AUTOSAR XML (schema 4-0-3)
standard types defined: Boolean, UInt16
package /AUTOSAR_Platform/DataConstrs
  range DC_Boolean: raw 0..1
  range DC_UInt16: raw 0..65535
package /PATAC/MSM/ComponentTypes
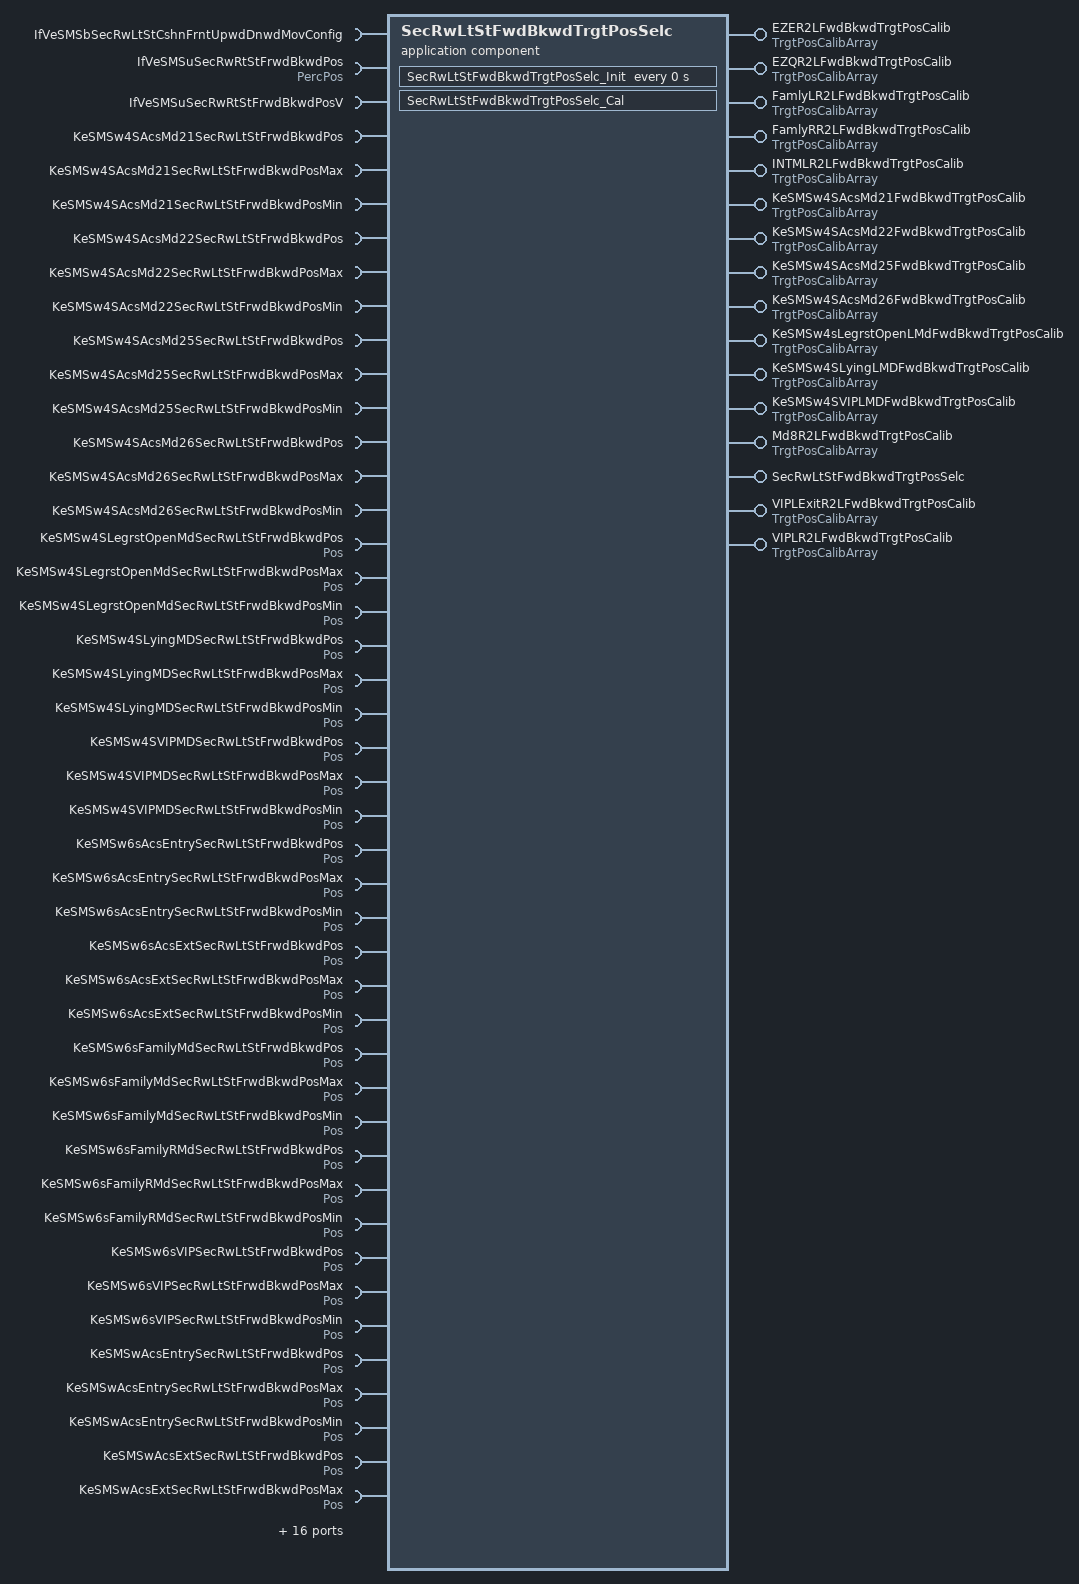
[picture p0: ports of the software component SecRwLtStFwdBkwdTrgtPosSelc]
  application sw component type SecRwLtStFwdBkwdTrgtPosSelc
    16 x provide port:
      EZER2LFwdBkwdTrgtPosCalib: nonqueued-sender-com-spec{data-element=TrgtPosArray, init-value=[4095, 4095, 4095]}, provided-interface=TrgtPosCalibArray
      EZQR2LFwdBkwdTrgtPosCalib: nonqueued-sender-com-spec{data-element=TrgtPosArray, init-value=[4095, 4095, 4095]}, provided-interface=TrgtPosCalibArray
      FamlyLR2LFwdBkwdTrgtPosCalib: nonqueued-sender-com-spec{data-element=TrgtPosArray, init-value=[4095, 4095, 4095]}, provided-interface=TrgtPosCalibArray
      FamlyRR2LFwdBkwdTrgtPosCalib: nonqueued-sender-com-spec{data-element=TrgtPosArray, init-value=[4095, 4095, 4095]}, provided-interface=TrgtPosCalibArray
      INTMLR2LFwdBkwdTrgtPosCalib: nonqueued-sender-com-spec{data-element=TrgtPosArray, init-value=[4095, 4095, 4095]}, provided-interface=TrgtPosCalibArray
      KeSMSw4SAcsMd21FwdBkwdTrgtPosCalib: nonqueued-sender-com-spec{data-element=TrgtPosArray, init-value=[4095, 4095, 4095]}, provided-interface=TrgtPosCalibArray
      KeSMSw4SAcsMd22FwdBkwdTrgtPosCalib: nonqueued-sender-com-spec{data-element=TrgtPosArray, init-value=[4095, 4095, 4095]}, provided-interface=TrgtPosCalibArray
      KeSMSw4SAcsMd25FwdBkwdTrgtPosCalib: nonqueued-sender-com-spec{data-element=TrgtPosArray, init-value=[4095, 4095, 4095]}, provided-interface=TrgtPosCalibArray
      KeSMSw4SAcsMd26FwdBkwdTrgtPosCalib: nonqueued-sender-com-spec{data-element=TrgtPosArray, init-value=[4095, 4095, 4095]}, provided-interface=TrgtPosCalibArray
      KeSMSw4sLegrstOpenLMdFwdBkwdTrgtPosCalib: nonqueued-sender-com-spec{data-element=TrgtPosArray, init-value=[4095, 4095, 4095]}, provided-interface=TrgtPosCalibArray
      KeSMSw4SLyingLMDFwdBkwdTrgtPosCalib: nonqueued-sender-com-spec{data-element=TrgtPosArray, init-value=[4095, 4095, 4095]}, provided-interface=TrgtPosCalibArray
      KeSMSw4SVIPLMDFwdBkwdTrgtPosCalib: nonqueued-sender-com-spec{data-element=TrgtPosArray, init-value=[4095, 4095, 4095]}, provided-interface=TrgtPosCalibArray
      Md8R2LFwdBkwdTrgtPosCalib: nonqueued-sender-com-spec{data-element=TrgtPosArray, init-value=[4095, 4095, 4095]}, provided-interface=TrgtPosCalibArray
      SecRwLtStFwdBkwdTrgtPosSelc: server-com-spec{operation=Cal, queue-length=1}, provided-interface=SecRwLtStFwdBkwdTrgtPosSelc
      VIPLExitR2LFwdBkwdTrgtPosCalib: nonqueued-sender-com-spec{data-element=TrgtPosArray, init-value=[4095, 4095, 4095]}, provided-interface=TrgtPosCalibArray
      VIPLR2LFwdBkwdTrgtPosCalib: nonqueued-sender-com-spec{data-element=TrgtPosArray, init-value=[4095, 4095, 4095]}, provided-interface=TrgtPosCalibArray
    60 x require port:
      IfVeSMSbSecRwLtStCshnFrntUpwdDnwdMovConfig: nonqueued-receiver-com-spec{data-element=IfVeSMSbSecRwLtStCshnFrntUpwdDnwdMovConfig/Val, filter=data-filter-type=ALWAYS, init-value=0}, required-interface=IfVeSMSbSecRwLtStCshnFrntUpwdDnwdMovConfig
      IfVeSMSuSecRwRtStFrwdBkwdPos: nonqueued-receiver-com-spec{data-element=PercPos/Val, filter=data-filter-type=ALWAYS, init-value=0}, required-interface=PercPos
      IfVeSMSuSecRwRtStFrwdBkwdPosV: nonqueued-receiver-com-spec{data-element=IfVeSMSuSecRwRtStFrwdBkwdPosV/Val, filter=data-filter-type=ALWAYS, init-value=0}, required-interface=IfVeSMSuSecRwRtStFrwdBkwdPosV
      KeSMSw4SAcsMd21SecRwLtStFrwdBkwdPos: parameter-require-com-spec{init-value=0, parameter=KeSMSw4SAcsMd21SecRwLtStFrwdBkwdPos/Val}, required-interface=KeSMSw4SAcsMd21SecRwLtStFrwdBkwdPos
      KeSMSw4SAcsMd21SecRwLtStFrwdBkwdPosMax: parameter-require-com-spec{init-value=0, parameter=KeSMSw4SAcsMd21SecRwLtStFrwdBkwdPosMax/Val}, required-interface=KeSMSw4SAcsMd21SecRwLtStFrwdBkwdPosMax
      KeSMSw4SAcsMd21SecRwLtStFrwdBkwdPosMin: parameter-require-com-spec{init-value=0, parameter=KeSMSw4SAcsMd21SecRwLtStFrwdBkwdPosMin/Val}, required-interface=KeSMSw4SAcsMd21SecRwLtStFrwdBkwdPosMin
      KeSMSw4SAcsMd22SecRwLtStFrwdBkwdPos: parameter-require-com-spec{init-value=0, parameter=KeSMSw4SAcsMd22SecRwLtStFrwdBkwdPos/Val}, required-interface=KeSMSw4SAcsMd22SecRwLtStFrwdBkwdPos
      KeSMSw4SAcsMd22SecRwLtStFrwdBkwdPosMax: parameter-require-com-spec{init-value=0, parameter=KeSMSw4SAcsMd22SecRwLtStFrwdBkwdPosMax/Val}, required-interface=KeSMSw4SAcsMd22SecRwLtStFrwdBkwdPosMax
      KeSMSw4SAcsMd22SecRwLtStFrwdBkwdPosMin: parameter-require-com-spec{init-value=0, parameter=KeSMSw4SAcsMd22SecRwLtStFrwdBkwdPosMin/Val}, required-interface=KeSMSw4SAcsMd22SecRwLtStFrwdBkwdPosMin
      KeSMSw4SAcsMd25SecRwLtStFrwdBkwdPos: parameter-require-com-spec{init-value=0, parameter=KeSMSw4SAcsMd25SecRwLtStFrwdBkwdPos/Val}, required-interface=KeSMSw4SAcsMd25SecRwLtStFrwdBkwdPos
      KeSMSw4SAcsMd25SecRwLtStFrwdBkwdPosMax: parameter-require-com-spec{init-value=0, parameter=KeSMSw4SAcsMd25SecRwLtStFrwdBkwdPosMax/Val}, required-interface=KeSMSw4SAcsMd25SecRwLtStFrwdBkwdPosMax
      KeSMSw4SAcsMd25SecRwLtStFrwdBkwdPosMin: parameter-require-com-spec{init-value=0, parameter=KeSMSw4SAcsMd25SecRwLtStFrwdBkwdPosMin/Val}, required-interface=KeSMSw4SAcsMd25SecRwLtStFrwdBkwdPosMin
      KeSMSw4SAcsMd26SecRwLtStFrwdBkwdPos: parameter-require-com-spec{init-value=0, parameter=KeSMSw4SAcsMd26SecRwLtStFrwdBkwdPos/Val}, required-interface=KeSMSw4SAcsMd26SecRwLtStFrwdBkwdPos
      KeSMSw4SAcsMd26SecRwLtStFrwdBkwdPosMax: parameter-require-com-spec{init-value=0, parameter=KeSMSw4SAcsMd26SecRwLtStFrwdBkwdPosMax/Val}, required-interface=KeSMSw4SAcsMd26SecRwLtStFrwdBkwdPosMax
      KeSMSw4SAcsMd26SecRwLtStFrwdBkwdPosMin: parameter-require-com-spec{init-value=0, parameter=KeSMSw4SAcsMd26SecRwLtStFrwdBkwdPosMin/Val}, required-interface=KeSMSw4SAcsMd26SecRwLtStFrwdBkwdPosMin
      KeSMSw4SLegrstOpenMdSecRwLtStFrwdBkwdPos: parameter-require-com-spec{init-value=2920, parameter=Pos/Val}, required-interface=Pos
      KeSMSw4SLegrstOpenMdSecRwLtStFrwdBkwdPosMax: parameter-require-com-spec{init-value=2920, parameter=Pos/Val}, required-interface=Pos
      KeSMSw4SLegrstOpenMdSecRwLtStFrwdBkwdPosMin: parameter-require-com-spec{init-value=2920, parameter=Pos/Val}, required-interface=Pos
      KeSMSw4SLyingMDSecRwLtStFrwdBkwdPos: parameter-require-com-spec{init-value=2920, parameter=Pos/Val}, required-interface=Pos
      KeSMSw4SLyingMDSecRwLtStFrwdBkwdPosMax: parameter-require-com-spec{init-value=2920, parameter=Pos/Val}, required-interface=Pos
      KeSMSw4SLyingMDSecRwLtStFrwdBkwdPosMin: parameter-require-com-spec{init-value=2920, parameter=Pos/Val}, required-interface=Pos
      KeSMSw4SVIPMDSecRwLtStFrwdBkwdPos: parameter-require-com-spec{init-value=2920, parameter=Pos/Val}, required-interface=Pos
      KeSMSw4SVIPMDSecRwLtStFrwdBkwdPosMax: parameter-require-com-spec{init-value=2920, parameter=Pos/Val}, required-interface=Pos
      KeSMSw4SVIPMDSecRwLtStFrwdBkwdPosMin: parameter-require-com-spec{init-value=2920, parameter=Pos/Val}, required-interface=Pos
      KeSMSw6sAcsEntrySecRwLtStFrwdBkwdPos: parameter-require-com-spec{init-value=727, parameter=Pos/Val}, required-interface=Pos
      KeSMSw6sAcsEntrySecRwLtStFrwdBkwdPosMax: parameter-require-com-spec{init-value=727, parameter=Pos/Val}, required-interface=Pos
      KeSMSw6sAcsEntrySecRwLtStFrwdBkwdPosMin: parameter-require-com-spec{init-value=727, parameter=Pos/Val}, required-interface=Pos
      KeSMSw6sAcsExtSecRwLtStFrwdBkwdPos: parameter-require-com-spec{init-value=727, parameter=Pos/Val}, required-interface=Pos
      KeSMSw6sAcsExtSecRwLtStFrwdBkwdPosMax: parameter-require-com-spec{init-value=727, parameter=Pos/Val}, required-interface=Pos
      KeSMSw6sAcsExtSecRwLtStFrwdBkwdPosMin: parameter-require-com-spec{init-value=727, parameter=Pos/Val}, required-interface=Pos
      KeSMSw6sFamilyMdSecRwLtStFrwdBkwdPos: parameter-require-com-spec{init-value=0, parameter=Pos/Val}, required-interface=Pos
      KeSMSw6sFamilyMdSecRwLtStFrwdBkwdPosMax: parameter-require-com-spec{init-value=0, parameter=Pos/Val}, required-interface=Pos
      KeSMSw6sFamilyMdSecRwLtStFrwdBkwdPosMin: parameter-require-com-spec{init-value=0, parameter=Pos/Val}, required-interface=Pos
      KeSMSw6sFamilyRMdSecRwLtStFrwdBkwdPos: parameter-require-com-spec{init-value=0, parameter=Pos/Val}, required-interface=Pos
      KeSMSw6sFamilyRMdSecRwLtStFrwdBkwdPosMax: parameter-require-com-spec{init-value=0, parameter=Pos/Val}, required-interface=Pos
      KeSMSw6sFamilyRMdSecRwLtStFrwdBkwdPosMin: parameter-require-com-spec{init-value=0, parameter=Pos/Val}, required-interface=Pos
      KeSMSw6sVIPSecRwLtStFrwdBkwdPos: parameter-require-com-spec{init-value=2920, parameter=Pos/Val}, required-interface=Pos
      KeSMSw6sVIPSecRwLtStFrwdBkwdPosMax: parameter-require-com-spec{init-value=2920, parameter=Pos/Val}, required-interface=Pos
      KeSMSw6sVIPSecRwLtStFrwdBkwdPosMin: parameter-require-com-spec{init-value=2920, parameter=Pos/Val}, required-interface=Pos
      KeSMSwAcsEntrySecRwLtStFrwdBkwdPos: parameter-require-com-spec{init-value=727, parameter=Pos/Val}, required-interface=Pos
      KeSMSwAcsEntrySecRwLtStFrwdBkwdPosMax: parameter-require-com-spec{init-value=727, parameter=Pos/Val}, required-interface=Pos
      KeSMSwAcsEntrySecRwLtStFrwdBkwdPosMin: parameter-require-com-spec{init-value=727, parameter=Pos/Val}, required-interface=Pos
      KeSMSwAcsExtSecRwLtStFrwdBkwdPos: parameter-require-com-spec{init-value=727, parameter=Pos/Val}, required-interface=Pos
      KeSMSwAcsExtSecRwLtStFrwdBkwdPosMax: parameter-require-com-spec{init-value=727, parameter=Pos/Val}, required-interface=Pos
      KeSMSwAcsExtSecRwLtStFrwdBkwdPosMin: parameter-require-com-spec{init-value=727, parameter=Pos/Val}, required-interface=Pos
      KeSMSwAcsMd8SecRwLtStFrwdBkwdPos: parameter-require-com-spec{init-value=0, parameter=Pos/Val}, required-interface=Pos
      KeSMSwAcsMd8SecRwLtStFrwdBkwdPosMax: parameter-require-com-spec{init-value=0, parameter=Pos/Val}, required-interface=Pos
      KeSMSwAcsMd8SecRwLtStFrwdBkwdPosMin: parameter-require-com-spec{init-value=0, parameter=Pos/Val}, required-interface=Pos
      KeSMSwFamilyMdSecRwLtStFrwdBkwdPos: parameter-require-com-spec{init-value=0, parameter=Pos/Val}, required-interface=Pos
      KeSMSwFamilyMdSecRwLtStFrwdBkwdPosMax: parameter-require-com-spec{init-value=0, parameter=Pos/Val}, required-interface=Pos
      KeSMSwFamilyMdSecRwLtStFrwdBkwdPosMin: parameter-require-com-spec{init-value=0, parameter=Pos/Val}, required-interface=Pos
      KeSMSwFamilyRMdSecRwLtStFrwdBkwdPos: parameter-require-com-spec{init-value=0, parameter=Pos/Val}, required-interface=Pos
      KeSMSwFamilyRMdSecRwLtStFrwdBkwdPosMax: parameter-require-com-spec{init-value=0, parameter=Pos/Val}, required-interface=Pos
      KeSMSwFamilyRMdSecRwLtStFrwdBkwdPosMin: parameter-require-com-spec{init-value=0, parameter=Pos/Val}, required-interface=Pos
      KeSMSwVIPSecRwLtStFrwdBkwdPos: parameter-require-com-spec{init-value=2920, parameter=Pos/Val}, required-interface=Pos
      KeSMSwVIPSecRwLtStFrwdBkwdPosMax: parameter-require-com-spec{init-value=2920, parameter=Pos/Val}, required-interface=Pos
      KeSMSwVIPSecRwLtStFrwdBkwdPosMin: parameter-require-com-spec{init-value=2920, parameter=Pos/Val}, required-interface=Pos
      StNumFlg: required-interface=StNumFlg
        required-com-specs:
          data-element=Is4s, filter=data-filter-type=ALWAYS, init-value=0
          data-element=Is6s, filter=data-filter-type=ALWAYS, init-value=0
          data-element=Is6s7s, filter=data-filter-type=ALWAYS, init-value=0
          data-element=Is7s, filter=data-filter-type=ALWAYS, init-value=0
      VIPL557TrgtPos: required-com-specs=[VIPL557TrgtPos/Get, VIPL557TrgtPos/Set], required-interface=VIPL557TrgtPos
      VIPLExit557TrgtPos: required-com-specs=[VIPLExit557TrgtPos/Get, VIPLExit557TrgtPos/Set], required-interface=VIPLExit557TrgtPos
    behavior SecRwLtStFwdBkwdTrgtPosSelc_InternalBehavior
      operation invoked event OIT_SecRwLtStFwdBkwdTrgtPosSelc_Cal_SecRwLtStFwdBkwdTrgtPosSelc_Cal: start-on-event=SecRwLtStFwdBkwdTrgtPosSelc_Cal, operation=SecRwLtStFwdBkwdTrgtPosSelc.Cal
      timing event SecRwLtStFwdBkwdTrgtPosSelc_InitEvent: start-on-event=SecRwLtStFwdBkwdTrgtPosSelc_Init, period=0
      runnable SecRwLtStFwdBkwdTrgtPosSelc_Cal
        data-receive-point-by-arguments:
          7 x access:
            REC_IfVeSMSbSecRwLtStCshnFrntUpwdDnwdMovConfig_Val: accessed-variable=IfVeSMSbSecRwLtStCshnFrntUpwdDnwdMovConfig.Val
            REC_IfVeSMSuSecRwRtStFrwdBkwdPos_Val: accessed-variable=IfVeSMSuSecRwRtStFrwdBkwdPos.Val
            REC_IfVeSMSuSecRwRtStFrwdBkwdPosV_Val: accessed-variable=IfVeSMSuSecRwRtStFrwdBkwdPosV.Val
            REC_StNumFlg_Is4s: accessed-variable=StNumFlg.Is4s
            REC_StNumFlg_Is6s: accessed-variable=StNumFlg.Is6s
            REC_StNumFlg_Is6s7s: accessed-variable=StNumFlg.Is6s7s
            REC_StNumFlg_Is7s: accessed-variable=StNumFlg.Is7s
        data-send-points:
          15 x access:
            SEND_EZER2LFwdBkwdTrgtPosCalib_TrgtPosArray: accessed-variable=EZER2LFwdBkwdTrgtPosCalib.TrgtPosArray
            SEND_EZQR2LFwdBkwdTrgtPosCalib_TrgtPosArray: accessed-variable=EZQR2LFwdBkwdTrgtPosCalib.TrgtPosArray
            SEND_FamlyLR2LFwdBkwdTrgtPosCalib_TrgtPosArray: accessed-variable=FamlyLR2LFwdBkwdTrgtPosCalib.TrgtPosArray
            SEND_FamlyRR2LFwdBkwdTrgtPosCalib_TrgtPosArray: accessed-variable=FamlyRR2LFwdBkwdTrgtPosCalib.TrgtPosArray
            SEND_INTMLR2LFwdBkwdTrgtPosCalib_TrgtPosArray: accessed-variable=INTMLR2LFwdBkwdTrgtPosCalib.TrgtPosArray
            SEND_KeSMSw4SAcsMd21FwdBkwdTrgtPosCalib_TrgtPosArray: accessed-variable=KeSMSw4SAcsMd21FwdBkwdTrgtPosCalib.TrgtPosArray
            SEND_KeSMSw4SAcsMd22FwdBkwdTrgtPosCalib_TrgtPosArray: accessed-variable=KeSMSw4SAcsMd22FwdBkwdTrgtPosCalib.TrgtPosArray
            SEND_KeSMSw4SAcsMd25FwdBkwdTrgtPosCalib_TrgtPosArray: accessed-variable=KeSMSw4SAcsMd25FwdBkwdTrgtPosCalib.TrgtPosArray
            SEND_KeSMSw4SAcsMd26FwdBkwdTrgtPosCalib_TrgtPosArray: accessed-variable=KeSMSw4SAcsMd26FwdBkwdTrgtPosCalib.TrgtPosArray
            SEND_KeSMSw4sLgrstOpenLFwdBkwdTrgtPosCalib_TrgtPosArray: accessed-variable=KeSMSw4sLegrstOpenLMdFwdBkwdTrgtPosCalib.TrgtPosArray
            SEND_KeSMSw4SLyingLFwdBkwdTrgtPosCalib_TrgtPosArray: accessed-variable=KeSMSw4SLyingLMDFwdBkwdTrgtPosCalib.TrgtPosArray
            SEND_KeSMSw4SVIPLFwdBkwdTrgtPosCalib_TrgtPosArray: accessed-variable=KeSMSw4SVIPLMDFwdBkwdTrgtPosCalib.TrgtPosArray
            SEND_Md8R2LFwdBkwdTrgtPosCalib_TrgtPosArray: accessed-variable=Md8R2LFwdBkwdTrgtPosCalib.TrgtPosArray
            SEND_VIPLExitR2LFwdBkwdTrgtPosCalib_TrgtPosArray: accessed-variable=VIPLExitR2LFwdBkwdTrgtPosCalib.TrgtPosArray
            SEND_VIPLR2LFwdBkwdTrgtPosCalib_TrgtPosArray: accessed-variable=VIPLR2LFwdBkwdTrgtPosCalib.TrgtPosArray
        54 x parameter access:
          PA_KeSMSw4SAcsMd21SecRwLtStFrwdBkwdPos_Val: accessed-parameter=KeSMSw4SAcsMd21SecRwLtStFrwdBkwdPos.Val
          PA_KeSMSw4SAcsMd21SecRwLtStFrwdBkwdPosMax_Val: accessed-parameter=KeSMSw4SAcsMd21SecRwLtStFrwdBkwdPosMax.Val
          PA_KeSMSw4SAcsMd21SecRwLtStFrwdBkwdPosMin_Val: accessed-parameter=KeSMSw4SAcsMd21SecRwLtStFrwdBkwdPosMin.Val
          PA_KeSMSw4SAcsMd22SecRwLtStFrwdBkwdPos_Val: accessed-parameter=KeSMSw4SAcsMd22SecRwLtStFrwdBkwdPos.Val
          PA_KeSMSw4SAcsMd22SecRwLtStFrwdBkwdPosMax_Val: accessed-parameter=KeSMSw4SAcsMd22SecRwLtStFrwdBkwdPosMax.Val
          PA_KeSMSw4SAcsMd22SecRwLtStFrwdBkwdPosMin_Val: accessed-parameter=KeSMSw4SAcsMd22SecRwLtStFrwdBkwdPosMin.Val
          PA_KeSMSw4SAcsMd25SecRwLtStFrwdBkwdPos_Val: accessed-parameter=KeSMSw4SAcsMd25SecRwLtStFrwdBkwdPos.Val
          PA_KeSMSw4SAcsMd25SecRwLtStFrwdBkwdPosMax_Val: accessed-parameter=KeSMSw4SAcsMd25SecRwLtStFrwdBkwdPosMax.Val
          PA_KeSMSw4SAcsMd25SecRwLtStFrwdBkwdPosMin_Val: accessed-parameter=KeSMSw4SAcsMd25SecRwLtStFrwdBkwdPosMin.Val
          PA_KeSMSw4SAcsMd26SecRwLtStFrwdBkwdPos_Val: accessed-parameter=KeSMSw4SAcsMd26SecRwLtStFrwdBkwdPos.Val
          PA_KeSMSw4SAcsMd26SecRwLtStFrwdBkwdPosMax_Val: accessed-parameter=KeSMSw4SAcsMd26SecRwLtStFrwdBkwdPosMax.Val
          PA_KeSMSw4SAcsMd26SecRwLtStFrwdBkwdPosMin_Val: accessed-parameter=KeSMSw4SAcsMd26SecRwLtStFrwdBkwdPosMin.Val
          PA_KeSMSw4SLegrstOpenMdSecRwLtStFrwdBkwdPos_Val: accessed-parameter=KeSMSw4SLegrstOpenMdSecRwLtStFrwdBkwdPos.Val
          PA_KeSMSw4SLegrstOpenMdSecRwLtStFrwdBkwdPosMax_Val: accessed-parameter=KeSMSw4SLegrstOpenMdSecRwLtStFrwdBkwdPosMax.Val
          PA_KeSMSw4SLegrstOpenMdSecRwLtStFrwdBkwdPosMin_Val: accessed-parameter=KeSMSw4SLegrstOpenMdSecRwLtStFrwdBkwdPosMin.Val
          PA_KeSMSw4SLyingMDSecRwLtStFrwdBkwdPos_Val: accessed-parameter=KeSMSw4SLyingMDSecRwLtStFrwdBkwdPos.Val
          PA_KeSMSw4SLyingMDSecRwLtStFrwdBkwdPosMax_Val: accessed-parameter=KeSMSw4SLyingMDSecRwLtStFrwdBkwdPosMax.Val
          PA_KeSMSw4SLyingMDSecRwLtStFrwdBkwdPosMin_Val: accessed-parameter=KeSMSw4SLyingMDSecRwLtStFrwdBkwdPosMin.Val
          PA_KeSMSw4SVIPMDSecRwLtStFrwdBkwdPos_Val: accessed-parameter=KeSMSw4SVIPMDSecRwLtStFrwdBkwdPos.Val
          PA_KeSMSw4SVIPMDSecRwLtStFrwdBkwdPosMax_Val: accessed-parameter=KeSMSw4SVIPMDSecRwLtStFrwdBkwdPosMax.Val
          PA_KeSMSw4SVIPMDSecRwLtStFrwdBkwdPosMin_Val: accessed-parameter=KeSMSw4SVIPMDSecRwLtStFrwdBkwdPosMin.Val
          PA_KeSMSw6sAcsEntrySecRwLtStFrwdBkwdPos_Val: accessed-parameter=KeSMSw6sAcsEntrySecRwLtStFrwdBkwdPos.Val
          PA_KeSMSw6sAcsEntrySecRwLtStFrwdBkwdPosMax_Val: accessed-parameter=KeSMSw6sAcsEntrySecRwLtStFrwdBkwdPosMax.Val
          PA_KeSMSw6sAcsEntrySecRwLtStFrwdBkwdPosMin_Val: accessed-parameter=KeSMSw6sAcsEntrySecRwLtStFrwdBkwdPosMin.Val
          PA_KeSMSw6sAcsExtSecRwLtStFrwdBkwdPos_Val: accessed-parameter=KeSMSw6sAcsExtSecRwLtStFrwdBkwdPos.Val
          PA_KeSMSw6sAcsExtSecRwLtStFrwdBkwdPosMax_Val: accessed-parameter=KeSMSw6sAcsExtSecRwLtStFrwdBkwdPosMax.Val
          PA_KeSMSw6sAcsExtSecRwLtStFrwdBkwdPosMin_Val: accessed-parameter=KeSMSw6sAcsExtSecRwLtStFrwdBkwdPosMin.Val
          PA_KeSMSw6sFamilyMdSecRwLtStFrwdBkwdPos_Val: accessed-parameter=KeSMSw6sFamilyMdSecRwLtStFrwdBkwdPos.Val
          PA_KeSMSw6sFamilyMdSecRwLtStFrwdBkwdPosMax_Val: accessed-parameter=KeSMSw6sFamilyMdSecRwLtStFrwdBkwdPosMax.Val
          PA_KeSMSw6sFamilyMdSecRwLtStFrwdBkwdPosMin_Val: accessed-parameter=KeSMSw6sFamilyMdSecRwLtStFrwdBkwdPosMin.Val
          PA_KeSMSw6sFamilyRMdSecRwLtStFrwdBkwdPos_Val: accessed-parameter=KeSMSw6sFamilyRMdSecRwLtStFrwdBkwdPos.Val
          PA_KeSMSw6sFamilyRMdSecRwLtStFrwdBkwdPosMax_Val: accessed-parameter=KeSMSw6sFamilyRMdSecRwLtStFrwdBkwdPosMax.Val
          PA_KeSMSw6sFamilyRMdSecRwLtStFrwdBkwdPosMin_Val: accessed-parameter=KeSMSw6sFamilyRMdSecRwLtStFrwdBkwdPosMin.Val
          PA_KeSMSw6sVIPSecRwLtStFrwdBkwdPos_Val: accessed-parameter=KeSMSw6sVIPSecRwLtStFrwdBkwdPos.Val
          PA_KeSMSw6sVIPSecRwLtStFrwdBkwdPosMax_Val: accessed-parameter=KeSMSw6sVIPSecRwLtStFrwdBkwdPosMax.Val
          PA_KeSMSw6sVIPSecRwLtStFrwdBkwdPosMin_Val: accessed-parameter=KeSMSw6sVIPSecRwLtStFrwdBkwdPosMin.Val
          PA_KeSMSwAcsEntrySecRwLtStFrwdBkwdPos_Val: accessed-parameter=KeSMSwAcsEntrySecRwLtStFrwdBkwdPos.Val
          PA_KeSMSwAcsEntrySecRwLtStFrwdBkwdPosMax_Val: accessed-parameter=KeSMSwAcsEntrySecRwLtStFrwdBkwdPosMax.Val
          PA_KeSMSwAcsEntrySecRwLtStFrwdBkwdPosMin_Val: accessed-parameter=KeSMSwAcsEntrySecRwLtStFrwdBkwdPosMin.Val
          PA_KeSMSwAcsExtSecRwLtStFrwdBkwdPos_Val: accessed-parameter=KeSMSwAcsExtSecRwLtStFrwdBkwdPos.Val
          PA_KeSMSwAcsExtSecRwLtStFrwdBkwdPosMax_Val: accessed-parameter=KeSMSwAcsExtSecRwLtStFrwdBkwdPosMax.Val
          PA_KeSMSwAcsExtSecRwLtStFrwdBkwdPosMin_Val: accessed-parameter=KeSMSwAcsExtSecRwLtStFrwdBkwdPosMin.Val
          PA_KeSMSwAcsMd8SecRwLtStFrwdBkwdPos_Val: accessed-parameter=KeSMSwAcsMd8SecRwLtStFrwdBkwdPos.Val
          PA_KeSMSwAcsMd8SecRwLtStFrwdBkwdPosMax_Val: accessed-parameter=KeSMSwAcsMd8SecRwLtStFrwdBkwdPosMax.Val
          PA_KeSMSwAcsMd8SecRwLtStFrwdBkwdPosMin_Val: accessed-parameter=KeSMSwAcsMd8SecRwLtStFrwdBkwdPosMin.Val
          PA_KeSMSwFamilyMdSecRwLtStFrwdBkwdPos_Val: accessed-parameter=KeSMSwFamilyMdSecRwLtStFrwdBkwdPos.Val
          PA_KeSMSwFamilyMdSecRwLtStFrwdBkwdPosMax_Val: accessed-parameter=KeSMSwFamilyMdSecRwLtStFrwdBkwdPosMax.Val
          PA_KeSMSwFamilyMdSecRwLtStFrwdBkwdPosMin_Val: accessed-parameter=KeSMSwFamilyMdSecRwLtStFrwdBkwdPosMin.Val
          PA_KeSMSwFamilyRMdSecRwLtStFrwdBkwdPos_Val: accessed-parameter=KeSMSwFamilyRMdSecRwLtStFrwdBkwdPos.Val
          PA_KeSMSwFamilyRMdSecRwLtStFrwdBkwdPosMax_Val: accessed-parameter=KeSMSwFamilyRMdSecRwLtStFrwdBkwdPosMax.Val
          PA_KeSMSwFamilyRMdSecRwLtStFrwdBkwdPosMin_Val: accessed-parameter=KeSMSwFamilyRMdSecRwLtStFrwdBkwdPosMin.Val
          PA_KeSMSwVIPSecRwLtStFrwdBkwdPos_Val: accessed-parameter=KeSMSwVIPSecRwLtStFrwdBkwdPos.Val
          PA_KeSMSwVIPSecRwLtStFrwdBkwdPosMax_Val: accessed-parameter=KeSMSwVIPSecRwLtStFrwdBkwdPosMax.Val
          PA_KeSMSwVIPSecRwLtStFrwdBkwdPosMin_Val: accessed-parameter=KeSMSwVIPSecRwLtStFrwdBkwdPosMin.Val
        sync call SC_VIPL557TrgtPos_Get: operation=VIPL557TrgtPos.Get, timeout=0
        sync call SC_VIPLExit557TrgtPos_Get: operation=VIPLExit557TrgtPos.Get, timeout=0
      runnable SecRwLtStFwdBkwdTrgtPosSelc_Init
        54 x parameter access:
          PA_KeSMSw4SAcsMd21SecRwLtStFrwdBkwdPos_Val: accessed-parameter=KeSMSw4SAcsMd21SecRwLtStFrwdBkwdPos.Val
          PA_KeSMSw4SAcsMd21SecRwLtStFrwdBkwdPosMax_Val: accessed-parameter=KeSMSw4SAcsMd21SecRwLtStFrwdBkwdPosMax.Val
          PA_KeSMSw4SAcsMd21SecRwLtStFrwdBkwdPosMin_Val: accessed-parameter=KeSMSw4SAcsMd21SecRwLtStFrwdBkwdPosMin.Val
          PA_KeSMSw4SAcsMd22SecRwLtStFrwdBkwdPos_Val: accessed-parameter=KeSMSw4SAcsMd22SecRwLtStFrwdBkwdPos.Val
          PA_KeSMSw4SAcsMd22SecRwLtStFrwdBkwdPosMax_Val: accessed-parameter=KeSMSw4SAcsMd22SecRwLtStFrwdBkwdPosMax.Val
          PA_KeSMSw4SAcsMd22SecRwLtStFrwdBkwdPosMin_Val: accessed-parameter=KeSMSw4SAcsMd22SecRwLtStFrwdBkwdPosMin.Val
          PA_KeSMSw4SAcsMd25SecRwLtStFrwdBkwdPos_Val: accessed-parameter=KeSMSw4SAcsMd25SecRwLtStFrwdBkwdPos.Val
          PA_KeSMSw4SAcsMd25SecRwLtStFrwdBkwdPosMax_Val: accessed-parameter=KeSMSw4SAcsMd25SecRwLtStFrwdBkwdPosMax.Val
          PA_KeSMSw4SAcsMd25SecRwLtStFrwdBkwdPosMin_Val: accessed-parameter=KeSMSw4SAcsMd25SecRwLtStFrwdBkwdPosMin.Val
          PA_KeSMSw4SAcsMd26SecRwLtStFrwdBkwdPos_Val: accessed-parameter=KeSMSw4SAcsMd26SecRwLtStFrwdBkwdPos.Val
          PA_KeSMSw4SAcsMd26SecRwLtStFrwdBkwdPosMax_Val: accessed-parameter=KeSMSw4SAcsMd26SecRwLtStFrwdBkwdPosMax.Val
          PA_KeSMSw4SAcsMd26SecRwLtStFrwdBkwdPosMin_Val: accessed-parameter=KeSMSw4SAcsMd26SecRwLtStFrwdBkwdPosMin.Val
          PA_KeSMSw4SLegrstOpenMdSecRwLtStFrwdBkwdPos_Val: accessed-parameter=KeSMSw4SLegrstOpenMdSecRwLtStFrwdBkwdPos.Val
          PA_KeSMSw4SLegrstOpenMdSecRwLtStFrwdBkwdPosMax_Val: accessed-parameter=KeSMSw4SLegrstOpenMdSecRwLtStFrwdBkwdPosMax.Val
          PA_KeSMSw4SLegrstOpenMdSecRwLtStFrwdBkwdPosMin_Val: accessed-parameter=KeSMSw4SLegrstOpenMdSecRwLtStFrwdBkwdPosMin.Val
          PA_KeSMSw4SLyingMDSecRwLtStFrwdBkwdPos_Val: accessed-parameter=KeSMSw4SLyingMDSecRwLtStFrwdBkwdPos.Val
          PA_KeSMSw4SLyingMDSecRwLtStFrwdBkwdPosMax_Val: accessed-parameter=KeSMSw4SLyingMDSecRwLtStFrwdBkwdPosMax.Val
          PA_KeSMSw4SLyingMDSecRwLtStFrwdBkwdPosMin_Val: accessed-parameter=KeSMSw4SLyingMDSecRwLtStFrwdBkwdPosMin.Val
          PA_KeSMSw4SVIPMDSecRwLtStFrwdBkwdPos_Val: accessed-parameter=KeSMSw4SVIPMDSecRwLtStFrwdBkwdPos.Val
          PA_KeSMSw4SVIPMDSecRwLtStFrwdBkwdPosMax_Val: accessed-parameter=KeSMSw4SVIPMDSecRwLtStFrwdBkwdPosMax.Val
          PA_KeSMSw4SVIPMDSecRwLtStFrwdBkwdPosMin_Val: accessed-parameter=KeSMSw4SVIPMDSecRwLtStFrwdBkwdPosMin.Val
          PA_KeSMSw6sAcsEntrySecRwLtStFrwdBkwdPos_Val: accessed-parameter=KeSMSw6sAcsEntrySecRwLtStFrwdBkwdPos.Val
          PA_KeSMSw6sAcsEntrySecRwLtStFrwdBkwdPosMax_Val: accessed-parameter=KeSMSw6sAcsEntrySecRwLtStFrwdBkwdPosMax.Val
          PA_KeSMSw6sAcsEntrySecRwLtStFrwdBkwdPosMin_Val: accessed-parameter=KeSMSw6sAcsEntrySecRwLtStFrwdBkwdPosMin.Val
          PA_KeSMSw6sAcsExtSecRwLtStFrwdBkwdPos_Val: accessed-parameter=KeSMSw6sAcsExtSecRwLtStFrwdBkwdPos.Val
          PA_KeSMSw6sAcsExtSecRwLtStFrwdBkwdPosMax_Val: accessed-parameter=KeSMSw6sAcsExtSecRwLtStFrwdBkwdPosMax.Val
          PA_KeSMSw6sAcsExtSecRwLtStFrwdBkwdPosMin_Val: accessed-parameter=KeSMSw6sAcsExtSecRwLtStFrwdBkwdPosMin.Val
          PA_KeSMSw6sFamilyMdSecRwLtStFrwdBkwdPos_Val: accessed-parameter=KeSMSw6sFamilyMdSecRwLtStFrwdBkwdPos.Val
          PA_KeSMSw6sFamilyMdSecRwLtStFrwdBkwdPosMax_Val: accessed-parameter=KeSMSw6sFamilyMdSecRwLtStFrwdBkwdPosMax.Val
          PA_KeSMSw6sFamilyMdSecRwLtStFrwdBkwdPosMin_Val: accessed-parameter=KeSMSw6sFamilyMdSecRwLtStFrwdBkwdPosMin.Val
          PA_KeSMSw6sFamilyRMdSecRwLtStFrwdBkwdPos_Val: accessed-parameter=KeSMSw6sFamilyRMdSecRwLtStFrwdBkwdPos.Val
          PA_KeSMSw6sFamilyRMdSecRwLtStFrwdBkwdPosMax_Val: accessed-parameter=KeSMSw6sFamilyRMdSecRwLtStFrwdBkwdPosMax.Val
          PA_KeSMSw6sFamilyRMdSecRwLtStFrwdBkwdPosMin_Val: accessed-parameter=KeSMSw6sFamilyRMdSecRwLtStFrwdBkwdPosMin.Val
          PA_KeSMSw6sVIPSecRwLtStFrwdBkwdPos_Val: accessed-parameter=KeSMSw6sVIPSecRwLtStFrwdBkwdPos.Val
          PA_KeSMSw6sVIPSecRwLtStFrwdBkwdPosMax_Val: accessed-parameter=KeSMSw6sVIPSecRwLtStFrwdBkwdPosMax.Val
          PA_KeSMSw6sVIPSecRwLtStFrwdBkwdPosMin_Val: accessed-parameter=KeSMSw6sVIPSecRwLtStFrwdBkwdPosMin.Val
          PA_KeSMSwAcsEntrySecRwLtStFrwdBkwdPos_Val: accessed-parameter=KeSMSwAcsEntrySecRwLtStFrwdBkwdPos.Val
          PA_KeSMSwAcsEntrySecRwLtStFrwdBkwdPosMax_Val: accessed-parameter=KeSMSwAcsEntrySecRwLtStFrwdBkwdPosMax.Val
          PA_KeSMSwAcsEntrySecRwLtStFrwdBkwdPosMin_Val: accessed-parameter=KeSMSwAcsEntrySecRwLtStFrwdBkwdPosMin.Val
          PA_KeSMSwAcsExtSecRwLtStFrwdBkwdPos_Val: accessed-parameter=KeSMSwAcsExtSecRwLtStFrwdBkwdPos.Val
          PA_KeSMSwAcsExtSecRwLtStFrwdBkwdPosMax_Val: accessed-parameter=KeSMSwAcsExtSecRwLtStFrwdBkwdPosMax.Val
          PA_KeSMSwAcsExtSecRwLtStFrwdBkwdPosMin_Val: accessed-parameter=KeSMSwAcsExtSecRwLtStFrwdBkwdPosMin.Val
          PA_KeSMSwAcsMd8SecRwLtStFrwdBkwdPos_Val: accessed-parameter=KeSMSwAcsMd8SecRwLtStFrwdBkwdPos.Val
          PA_KeSMSwAcsMd8SecRwLtStFrwdBkwdPosMax_Val: accessed-parameter=KeSMSwAcsMd8SecRwLtStFrwdBkwdPosMax.Val
          PA_KeSMSwAcsMd8SecRwLtStFrwdBkwdPosMin_Val: accessed-parameter=KeSMSwAcsMd8SecRwLtStFrwdBkwdPosMin.Val
          PA_KeSMSwFamilyMdSecRwLtStFrwdBkwdPos_Val: accessed-parameter=KeSMSwFamilyMdSecRwLtStFrwdBkwdPos.Val
          PA_KeSMSwFamilyMdSecRwLtStFrwdBkwdPosMax_Val: accessed-parameter=KeSMSwFamilyMdSecRwLtStFrwdBkwdPosMax.Val
          PA_KeSMSwFamilyMdSecRwLtStFrwdBkwdPosMin_Val: accessed-parameter=KeSMSwFamilyMdSecRwLtStFrwdBkwdPosMin.Val
          PA_KeSMSwFamilyRMdSecRwLtStFrwdBkwdPos_Val: accessed-parameter=KeSMSwFamilyRMdSecRwLtStFrwdBkwdPos.Val
          PA_KeSMSwFamilyRMdSecRwLtStFrwdBkwdPosMax_Val: accessed-parameter=KeSMSwFamilyRMdSecRwLtStFrwdBkwdPosMax.Val
          PA_KeSMSwFamilyRMdSecRwLtStFrwdBkwdPosMin_Val: accessed-parameter=KeSMSwFamilyRMdSecRwLtStFrwdBkwdPosMin.Val
          PA_KeSMSwVIPSecRwLtStFrwdBkwdPos_Val: accessed-parameter=KeSMSwVIPSecRwLtStFrwdBkwdPos.Val
          PA_KeSMSwVIPSecRwLtStFrwdBkwdPosMax_Val: accessed-parameter=KeSMSwVIPSecRwLtStFrwdBkwdPosMax.Val
          PA_KeSMSwVIPSecRwLtStFrwdBkwdPosMin_Val: accessed-parameter=KeSMSwVIPSecRwLtStFrwdBkwdPosMin.Val
  swc implementation SecRwLtStFwdBkwdTrgtPosSelc_Implementation: behavior=SecRwLtStFwdBkwdTrgtPosSelc_InternalBehavior
    code-descriptors:
      code Default: artifact-descriptors=autosar-engineering-object={short-label=Default, category=SWSRC}
package /PATAC/MSM/ModeAdjust/CalPortInterface
  13 x parameter interface:
    KeSMSw4SAcsMd21SecRwLtStFrwdBkwdPos
      parameter data prototype Val: sw-calibration-access=READ-WRITE, type=UInt16
    KeSMSw4SAcsMd21SecRwLtStFrwdBkwdPosMax
      parameter data prototype Val: sw-calibration-access=READ-WRITE, type=UInt16
    KeSMSw4SAcsMd21SecRwLtStFrwdBkwdPosMin
      parameter data prototype Val: sw-calibration-access=READ-WRITE, type=UInt16
    KeSMSw4SAcsMd22SecRwLtStFrwdBkwdPos
      parameter data prototype Val: sw-calibration-access=READ-WRITE, type=UInt16
    KeSMSw4SAcsMd22SecRwLtStFrwdBkwdPosMax
      parameter data prototype Val: sw-calibration-access=READ-WRITE, type=UInt16
    KeSMSw4SAcsMd22SecRwLtStFrwdBkwdPosMin
      parameter data prototype Val: sw-calibration-access=READ-WRITE, type=UInt16
    KeSMSw4SAcsMd25SecRwLtStFrwdBkwdPos
      parameter data prototype Val: sw-calibration-access=READ-WRITE, type=UInt16
    KeSMSw4SAcsMd25SecRwLtStFrwdBkwdPosMax
      parameter data prototype Val: sw-calibration-access=READ-WRITE, type=UInt16
    KeSMSw4SAcsMd25SecRwLtStFrwdBkwdPosMin
      parameter data prototype Val: sw-calibration-access=READ-WRITE, type=UInt16
    KeSMSw4SAcsMd26SecRwLtStFrwdBkwdPos
      parameter data prototype Val: sw-calibration-access=READ-WRITE, type=UInt16
    KeSMSw4SAcsMd26SecRwLtStFrwdBkwdPosMax
      parameter data prototype Val: sw-calibration-access=READ-WRITE, type=UInt16
    KeSMSw4SAcsMd26SecRwLtStFrwdBkwdPosMin
      parameter data prototype Val: sw-calibration-access=READ-WRITE, type=UInt16
    Pos
      parameter data prototype Val: sw-calibration-access=READ-WRITE, type=UInt16
package /PATAC/MSM/ModeAdjust/DataType
  impl type TrgtPosCalibArray: category=ARRAY, sw-calibration-access=READ-ONLY, type-emitter=RTE  # 0:pos 1:max 2:min
    element Element: array-size=3, array-size-semantics=FIXED-SIZE, implementation-data-type=UInt16, invalid-value=0
package /PATAC/MSM/ModeAdjust/Interfaces
  sender receiver interface IfVeSMSuSecRwRtStFrwdBkwdPosV: invalidation-policy{data-element=IfVeSMSuSecRwRtStFrwdBkwdPosV/Val, handle-invalid=DONT-INVALIDATE}
    data Val: type=Boolean
package /PATAC/MSM/ModeAdjust/PortInterface
  client server interface SecRwLtStFwdBkwdTrgtPosSelc
    operation Cal
  client server interface VIPL557TrgtPos
    operation Get
      5 x arg, all with type=UInt16, direction=OUT, server-argument-impl-policy=USE-ARGUMENT-TYPE:
        SecRwLtStBkReclnTrgtPos
        SecRwLtStZeroTrgtPos
        SecRwLtStLgrstUpwdDnwdTrgtPos
        SecRwLtStLgrstInwdOtwdTrgtPos
        SecRwLtStFwdBkwdTrgtPos
    operation Set
      5 x arg, all with type=UInt16, direction=IN, server-argument-impl-policy=USE-ARGUMENT-TYPE:
        SecRwLtStBkReclnTrgtPos
        SecRwLtStZeroTrgtPos
        SecRwLtStLgrstUpwdDnwdTrgtPos
        SecRwLtStLgrstInwdOtwdTrgtPos
        SecRwLtStFwdBkwdTrgtPos
  client server interface VIPLExit557TrgtPos
    operation Get
      7 x arg, all with type=UInt16, direction=OUT, server-argument-impl-policy=USE-ARGUMENT-TYPE:
        SecRwLtStBkReclnTrgtPos
        SecRwLtStZeroTrgtPos
        SecRwLtStLgrstUpwdDnwdTrgtPos
        SecRwLtStLgrstInwdOtwdTrgtPos
        ThdRwLtStBkReclnTrgtPos
        ThdRwLtStFwdBkwdTrgtPos
        SecRwLtStFwdBkwdTrgtPos
    operation Set
  sender receiver interface PercPos: invalidation-policy{data-element=PercPos/Val, handle-invalid=DONT-INVALIDATE}
    data Val: type=UInt16
  sender receiver interface StNumFlg
    4 x data, all with type=Boolean:
      Is4s
      Is6s
      Is6s7s
      Is7s
    invalidation-policys:
      data-element=Is4s, handle-invalid=DONT-INVALIDATE
      data-element=Is6s, handle-invalid=DONT-INVALIDATE
      data-element=Is6s7s, handle-invalid=DONT-INVALIDATE
      data-element=Is7s, handle-invalid=DONT-INVALIDATE
  sender receiver interface TrgtPosCalibArray: invalidation-policy{data-element=TrgtPosArray, handle-invalid=DONT-INVALIDATE}
    data TrgtPosArray: type=TrgtPosCalibArray  # 0:Pos 1:Max 2:Min
package /PATAC/MSM/PortInterfaces
  sender receiver interface IfVeSMSbSecRwLtStCshnFrntUpwdDnwdMovConfig: invalidation-policy{data-element=IfVeSMSbSecRwLtStCshnFrntUpwdDnwdMovConfig/Val, handle-invalid=DONT-INVALIDATE}
    data Val: type=Boolean
